# STM32F373 register map
File version: 1.7
CPU: CM4 r1p0, little endian, MPU, FPU, 4 interrupt priority bits
Registers are 32-bit, read-write, reset 0x0 unless marked. A register's access mark holds for its fields unless they carry their own. Offsets are from the block's base; [hi:lo] are bit positions; {n}, {i} and the like mark numbered series.

## DAC2 — Digital-to-analog converter
Base 0x40009800
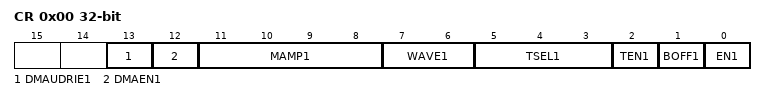
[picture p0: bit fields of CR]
0x00 CR — control register
  [n+12] DMAUDRIE{n} (n=1..1) — DAC channel{n} DMA Underrun Interrupt enable
    0=Disabled (DAC channel X DMA Underrun Interrupt disabled); 1=Enabled (DAC channel X DMA Underrun Interrupt enabled)
  [n+11] DMAEN{n} (n=1..1) — DAC channel{n} DMA enable
    0=Disabled (DAC channel X DMA mode disabled); 1=Enabled (DAC channel X DMA mode enabled)
  [n+10:n+7] MAMP{n} (n=1..1) — DAC channel{n} mask/amplitude selector
    0=Amp1 (Unmask bit0 of LFSR/ triangle amplitude equal to 1); 1=Amp3 (Unmask bits[1:0] of LFSR/ triangle amplitude equal to 3); 2=Amp7 (Unmask bits[2:0] of LFSR/ triangle amplitude equal to 7); 3=Amp15 (Unmask bits[3:0] of LFSR/ triangle amplitude equal to 15); 4=Amp31 (Unmask bits[4:0] of LFSR/ triangle amplitude equal to 31); 5=Amp63 (Unmask bits[5:0] of LFSR/ triangle amplitude equal 63); 6=Amp127 (Unmask bits[6:0] of LFSR/ triangle amplitude equal to 127); 7=Amp255 (Unmask bits[7:0] of LFSR/ triangle amplitude equal to 255); 8=Amp511 (Unmask bits[8:0] of LFSR/ triangle amplitude equal to 511); 9=Amp1023 (Unmask bits[9:0] of LFSR/ triangle amplitude equal to 1023); 10=Amp2047 (Unmask bits[10:0] of LFSR/ triangle amplitude equal to 2047); other=Amp4095 (Unmask bits[11:0] of LFSR/ triangle amplitude equal to 4095)
  [n+6:n+5] WAVE{n} (n=1..1) — DAC channel{n} noise/triangle wave generation enable
    0=Disabled (Wave generation disabled); 1=Noise wave generation enabled; other=Triangle wave generation enabled
  [5:3] TSEL1 — DAC channel1 trigger selection
    0=Tim6Trgo (Timer 6 TRGO event); 1=Tim3Trgo (Timer 3 TRGO event); 2=Tim7Trgo (Timer 7 TRGO event); 3=Tim18Trgo (Timer 18 TRGO event); 4=Tim2Trgo (Timer 2 TRGO event); 5=Tim4Trgo (Timer 4 TRGO event); 6=Exti9 (EXTI line 9); 7=Software trigger
  [n+1] TEN{n} (n=1..1) — DAC channel{n} trigger enable
    0=Disabled (DAC channel X trigger disabled); 1=Enabled (DAC channel X trigger enabled)
  [n] BOFF{n} (n=1..1) — DAC channel{n} output buffer disable
    0=Enabled (DAC channel X output buffer enabled); 1=Disabled (DAC channel X output buffer disabled)
  [n-1] EN{n} (n=1..1) — DAC channel{n} enable
    0=Disabled (DAC channel X disabled); 1=Enabled (DAC channel X enabled)
0x04 SWTRIGR wo — software trigger register
  [n-1] SWTRIG{n} (n=1..1) — DAC channel{n} software trigger
    0=Disabled (DAC channel X software trigger disabled); 1=Enabled (DAC channel X software trigger enabled)
{0x4+4i} DHR12R{i} (i=1..1) — channel{i} 12-bit right-aligned data holding register
  [11:0] DACCDHR — DAC channel1 12-bit right-aligned data
{0x8+4i} DHR12L{i} (i=1..1) — channel{i} 12-bit left aligned data holding register
  [15:4] DACCDHR — DAC channel1 12-bit left-aligned data
{0xC+4i} DHR8R{i} (i=1..1) — channel{i} 8-bit right aligned data holding register
  [7:0] DACCDHR — DAC channel1 8-bit right-aligned data
{0x28+4i} DOR{i} (i=1..1) ro — channel{i} data output register
  [11:0] DACCDOR — DAC channel1 data output
0x34 SR — DAC status register
  [n+12] DMAUDR{n} (n=1..1) — DAC channel{n} DMA underrun flag
    0=NoUnderrun (No DMA underrun error condition occurred for DAC channel x); 1=Underrun (DMA underrun error condition occurred for DAC channel x (the currently selected trigger is driving DAC channel1 conversion at a frequency higher than the DMA service capability rate))

## TIM6 — Basic timers
Base 0x40001000
Same registers: TIM7 0x40001400, TIM18 0x40009C00
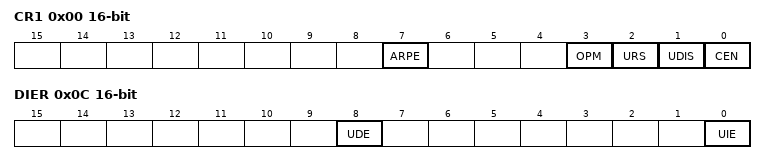
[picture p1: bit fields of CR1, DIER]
0x00 CR1 16-bit — control register 1
  [7] ARPE — Auto-reload preload enable
    0=Disabled (TIMx_APRR register is not buffered); 1=Enabled (TIMx_APRR register is buffered)
  [3] OPM — One-pulse mode
    0=Disabled (Counter is not stopped at update event); 1=Enabled (Counter stops counting at the next update event (clearing the CEN bit))
  [2] URS — Update request source
    0=AnyEvent (Any of counter overflow/underflow, setting UG, or update through slave mode, generates an update interrupt or DMA request); 1=CounterOnly (Only counter overflow/underflow generates an update interrupt or DMA request)
  [1] UDIS — Update disable
    0=Enabled (Update event enabled); 1=Disabled (Update event disabled)
  [0] CEN — Counter enable
    0=Disabled (Counter disabled); 1=Enabled (Counter enabled)
0x04 CR2 16-bit — control register 2
  [6:4] MMS — Master mode selection
    0=Reset (Use UG bit from TIMx_EGR register); 1=Enable (Use CNT bit from TIMx_CEN register); 2=Update (Use the update event)
0x0C DIER 16-bit — DMA/Interrupt enable register
  [8] UDE — Update DMA request enable
    0=Disabled (Update DMA request disabled); 1=Enabled (Update DMA request enabled)
  [0] UIE — Update interrupt enable
    0=Disabled (Update interrupt disabled); 1=Enabled (Update interrupt enabled)
0x10 SR 16-bit — status register
  [0] UIF write-0-clears — Update interrupt flag
    on read: 0=NoUpdateOccurred; 1=UpdatePending (Update interrupt pending) | on write: 0=Clear flag
0x14 EGR 16-bit wo — event generation register
  [0] UG — Update generation
    1=Update (Re-initializes the timer counter and generates an update of the registers.)
0x24 CNT 16-bit — counter
  [15:0] CNT — Low counter value
0x28 PSC 16-bit — prescaler
  [15:0] PSC — Prescaler value
0x2C ARR 16-bit reset 0xFFFF — auto-reload register
  [15:0] ARR — Low Auto-reload value

## DBGMCU — Debug support
Base 0xE0042000
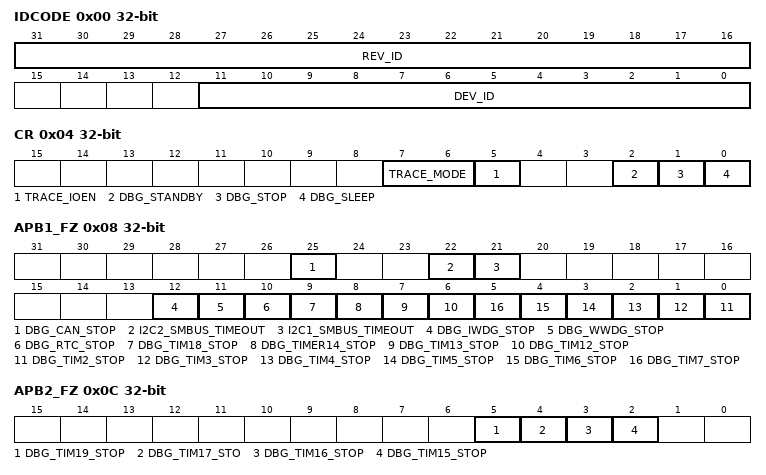
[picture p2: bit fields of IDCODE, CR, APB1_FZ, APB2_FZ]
0x00 IDCODE ro — MCU Device ID Code Register
  [31:16] REV_ID — Revision Identifier
  [11:0] DEV_ID — Device Identifier
0x04 CR — Debug MCU Configuration Register
  [7:6] TRACE_MODE — Trace pin assignment control
  [5] TRACE_IOEN — Trace pin assignment control
  [2] DBG_STANDBY — Debug Standby Mode
  [1] DBG_STOP — Debug Stop Mode
  [0] DBG_SLEEP — Debug Sleep mode
0x08 APB1_FZ — APB Low Freeze Register
  [25] DBG_CAN_STOP — Debug CAN stopped when core is halted
  [22] I2C2_SMBUS_TIMEOUT — SMBUS timeout mode stopped when Core is halted
  [21] I2C1_SMBUS_TIMEOUT — SMBUS timeout mode stopped when Core is halted
  [12] DBG_IWDG_STOP — Debug Independent Wachdog stopped when Core is halted
  [11] DBG_WWDG_STOP — Debug Window Wachdog stopped when Core is halted
  [10] DBG_RTC_STOP — Debug RTC stopped when Core is halted
  [9] DBG_TIM18_STOP — Debug Timer 18 stopped when Core is halted
  [8] DBG_TIMER14_STOP — Debug Timer 14 stopped when Core is halted
  [7] DBG_TIM13_STOP — Debug Timer 13 stopped when Core is halted
  [6] DBG_TIM12_STOP — Debug Timer 12 stopped when Core is halted
  [n-2] DBG_TIM{n}_STOP (n=2..7) — Debug Timer {n} stopped when Core is halted
0x0C APB2_FZ — APB High Freeze Register
  [5] DBG_TIM19_STOP — Debug Timer 19 stopped when Core is halted
  [4] DBG_TIM17_STO — Debug Timer 17 stopped when Core is halted
  [3] DBG_TIM16_STOP — Debug Timer 16 stopped when Core is halted
  [2] DBG_TIM15_STOP — Debug Timer 15 stopped when Core is halted

## COMP — General purpose comparators
Base 0x40010000
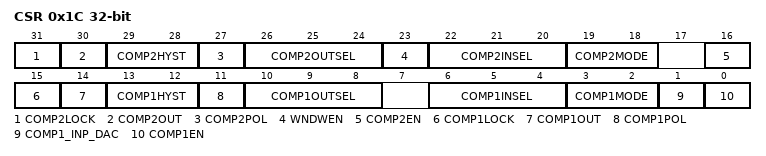
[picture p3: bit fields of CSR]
0x1C CSR access per field — control and status register
  [31] COMP2LOCK rw — Comparator 2 lock
  [30] COMP2OUT ro — Comparator 2 output
  [29:28] COMP2HYST rw — Comparator 2 hysteresis
  [27] COMP2POL rw — Comparator 2 output polarity
  [26:24] COMP2OUTSEL rw — Comparator 2 output selection
  [23] WNDWEN rw — Window mode enable
  [22:20] COMP2INSEL rw — Comparator 2 inverting input selection
  [19:18] COMP2MODE rw — Comparator 2 mode
  [16] COMP2EN rw — Comparator 2 enable
  [15] COMP1LOCK rw — Comparator 1 lock
  [14] COMP1OUT ro — Comparator 1 output
  [13:12] COMP1HYST rw — Comparator 1 hysteresis
  [11] COMP1POL rw — Comparator 1 output polarity
  [10:8] COMP1OUTSEL rw — Comparator 1 output selection
  [6:4] COMP1INSEL rw — Comparator 1 inverting input selection
  [3:2] COMP1MODE rw — Comparator 1 mode
  [1] COMP1_INP_DAC rw — Comparator 1 non inverting input connection to DAC output
  [0] COMP1EN rw — Comparator 1 enable
